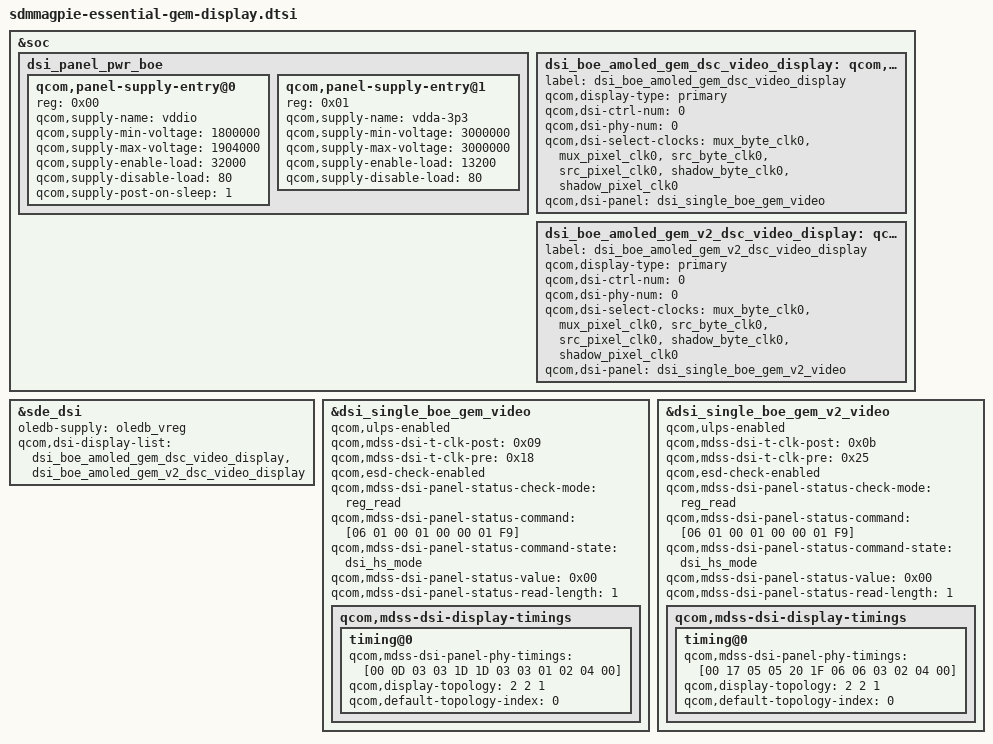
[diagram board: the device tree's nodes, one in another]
#include "dsi-panel-boe-gem-v2-video.dtsi"
#include "dsi-panel-boe-gem-video.dtsi"

&soc {
	dsi_panel_pwr_boe: dsi_panel_pwr_boe {
		#address-cells = <1>;
		#size-cells = <0>;

		qcom,panel-supply-entry@0 {
			reg = <0x00>;
			qcom,supply-name = "vddio";
			qcom,supply-min-voltage = <1800000>;
			qcom,supply-max-voltage = <1904000>;
			qcom,supply-enable-load = <32000>;
			qcom,supply-disable-load = <80>;
			qcom,supply-post-on-sleep = <1>;
		};

		qcom,panel-supply-entry@1 {
			reg = <0x01>;
			qcom,supply-name = "vdda-3p3";
			qcom,supply-min-voltage = <3000000>;
			qcom,supply-max-voltage = <3000000>;
			qcom,supply-enable-load = <13200>;
			qcom,supply-disable-load = <80>;
		};
	};

	dsi_boe_amoled_gem_dsc_video_display: qcom,dsi-display@22 {
		label = "dsi_boe_amoled_gem_dsc_video_display";
		qcom,display-type = "primary";

		qcom,dsi-ctrl-num = <0>;
		qcom,dsi-phy-num = <0>;
		qcom,dsi-select-clocks = "mux_byte_clk0", "mux_pixel_clk0", "src_byte_clk0", "src_pixel_clk0", "shadow_byte_clk0", "shadow_pixel_clk0";

		qcom,dsi-panel = <&dsi_single_boe_gem_video>;
	};

	dsi_boe_amoled_gem_v2_dsc_video_display: qcom,dsi-display@23 {
		label = "dsi_boe_amoled_gem_v2_dsc_video_display";
		qcom,display-type = "primary";

		qcom,dsi-ctrl-num = <0>;
		qcom,dsi-phy-num = <0>;
		qcom,dsi-select-clocks = "mux_byte_clk0", "mux_pixel_clk0", "src_byte_clk0", "src_pixel_clk0", "shadow_byte_clk0", "shadow_pixel_clk0";

		qcom,dsi-panel = <&dsi_single_boe_gem_v2_video>;
	};
};

&sde_dsi {
	oledb-supply = <&oledb_vreg>;

	qcom,dsi-display-list =
		<&dsi_boe_amoled_gem_dsc_video_display
		&dsi_boe_amoled_gem_v2_dsc_video_display>;
};

&dsi_single_boe_gem_video {
	qcom,ulps-enabled;
	qcom,mdss-dsi-t-clk-post = <0x09>;
	qcom,mdss-dsi-t-clk-pre = <0x18>;
	qcom,esd-check-enabled;
	qcom,mdss-dsi-panel-status-check-mode = "reg_read";
	qcom,mdss-dsi-panel-status-command = [06 01 00 01 00 00 01 F9];
	qcom,mdss-dsi-panel-status-command-state = "dsi_hs_mode";
	qcom,mdss-dsi-panel-status-value = <0x00>;
	qcom,mdss-dsi-panel-status-read-length = <1>;
	qcom,mdss-dsi-display-timings {
		timing@0 {
			qcom,mdss-dsi-panel-phy-timings = [00 0D 03 03 1D 1D 03 03 01 02 04 00];
			qcom,display-topology = <2 2 1>;
			qcom,default-topology-index = <0>;
		};
	};
};

&dsi_single_boe_gem_v2_video {
	qcom,ulps-enabled;
	qcom,mdss-dsi-t-clk-post = <0x0b>;
	qcom,mdss-dsi-t-clk-pre = <0x25>;
	qcom,esd-check-enabled;
	qcom,mdss-dsi-panel-status-check-mode = "reg_read";
	qcom,mdss-dsi-panel-status-command = [06 01 00 01 00 00 01 F9];
	qcom,mdss-dsi-panel-status-command-state = "dsi_hs_mode";
	qcom,mdss-dsi-panel-status-value = <0x00>;
	qcom,mdss-dsi-panel-status-read-length = <1>;
	qcom,mdss-dsi-display-timings {
		timing@0 {
			qcom,mdss-dsi-panel-phy-timings = [00 17 05 05 20 1F 06 06 03 02 04 00];
			qcom,display-topology = <2 2 1>;
			qcom,default-topology-index = <0>;
		};
	};
};
